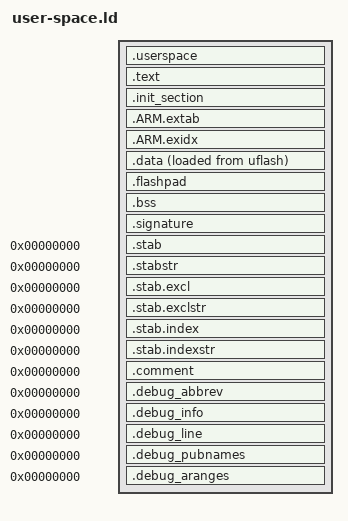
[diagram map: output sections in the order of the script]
/****************************************************************************
 * user-space.ld
 *
 *   Copyright (C) 2015 Gregory Nutt. All rights reserved.
 *   Author: Gregory Nutt <gnutt@nuttx.org>
 *
 * Redistribution and use in source and binary forms, with or without
 * modification, are permitted provided that the following conditions
 * are met:
 *
 * 1. Redistributions of source code must retain the above copyright
 *    notice, this list of conditions and the following disclaimer.
 * 2. Redistributions in binary form must reproduce the above copyright
 *    notice, this list of conditions and the following disclaimer in
 *    the documentation and/or other materials provided with the
 *    distribution.
 * 3. Neither the name NuttX nor the names of its contributors may be
 *    used to endorse or promote products derived from this software
 *    without specific prior written permission.
 *
 * THIS SOFTWARE IS PROVIDED BY THE COPYRIGHT HOLDERS AND CONTRIBUTORS
 * "AS IS" AND ANY EXPRESS OR IMPLIED WARRANTIES, INCLUDING, BUT NOT
 * LIMITED TO, THE IMPLIED WARRANTIES OF MERCHANTABILITY AND FITNESS
 * FOR A PARTICULAR PURPOSE ARE DISCLAIMED. IN NO EVENT SHALL THE
 * COPYRIGHT OWNER OR CONTRIBUTORS BE LIABLE FOR ANY DIRECT, INDIRECT,
 * INCIDENTAL, SPECIAL, EXEMPLARY, OR CONSEQUENTIAL DAMAGES (INCLUDING,
 * BUT NOT LIMITED TO, PROCUREMENT OF SUBSTITUTE GOODS OR SERVICES; LOSS
 * OF USE, DATA, OR PROFITS; OR BUSINESS INTERRUPTION) HOWEVER CAUSED
 * AND ON ANY THEORY OF LIABILITY, WHETHER IN CONTRACT, STRICT
 * LIABILITY, OR TORT (INCLUDING NEGLIGENCE OR OTHERWISE) ARISING IN
 * ANY WAY OUT OF THE USE OF THIS SOFTWARE, EVEN IF ADVISED OF THE
 * POSSIBILITY OF SUCH DAMAGE.
 *
 ****************************************************************************/

/* Include memory.ld before this script. */

EXTERN(userspace)
OUTPUT_ARCH(arm)

SECTIONS
{
    .userspace : {
        _stext = ABSOLUTE(.);
        KEEP(*(.userspace))
    } > uflash

    .text : {
        *(.text .text.*)
        *(.fixup)
        *(.gnu.warning)
        *(.rodata .rodata.*)
        *(.gnu.linkonce.t.*)
        *(.glue_7)
        *(.glue_7t)
        *(.got)
        *(.gcc_except_table)
        *(.gnu.linkonce.r.*)
    } > uflash

    .init_section : {
        _sinit = ABSOLUTE(.);
        KEEP(*(.init_array .init_array.*))
        _einit = ABSOLUTE(.);
    } > uflash

    .ARM.extab : {
        *(.ARM.extab*)
    } > uflash

    .ARM.exidx : {
        __exidx_start = ABSOLUTE(.);
        *(.ARM.exidx*)
        __exidx_end = ABSOLUTE(.);
    } > uflash

    .data : {
        _sdata = ABSOLUTE(.);
        *(.data .data.*)
        *(.gnu.linkonce.d.*)
        CONSTRUCTORS
        . = ALIGN(4);
        _edata = ABSOLUTE(.);
    } > usram AT > uflash

    _eronly = LOADADDR(.data);

    /* Pad the final loadable section to the STM32H7 flash write size. */
    .flashpad : {
        FILL(0xffffffff)
        BYTE(0xff)
        . = ALIGN(32);
        _etext = ABSOLUTE(.);
    } > uflash

    .bss (NOLOAD) : {
        _sbss = ABSOLUTE(.);
        *(.bss .bss.*)
        *(.gnu.linkonce.b.*)
        *(COMMON)
        /* The largest user static MPU region is 128 KiB. Its eight
         * subregions are 16 KiB; keep the following kernel heap outside
         * every user-accessible subregion, including alignment padding.
         */
        . = ALIGN(0x4000);
        _ebss = ABSOLUTE(.);
    } > usram

    ASSERT(_ebss <= ORIGIN(usram) + LENGTH(usram),
           "User data exceeds its protected SRAM window")
    ASSERT((_ebss & 0x3fff) == 0,
           "User bss end must align to an MPU subregion")

    /* The signature is appended at the end of the combined image. */
    .signature : {
        _boot_signature = ALIGN(4);
    } > uflash

    .stab 0 : { *(.stab) }
    .stabstr 0 : { *(.stabstr) }
    .stab.excl 0 : { *(.stab.excl) }
    .stab.exclstr 0 : { *(.stab.exclstr) }
    .stab.index 0 : { *(.stab.index) }
    .stab.indexstr 0 : { *(.stab.indexstr) }
    .comment 0 : { *(.comment) }
    .debug_abbrev 0 : { *(.debug_abbrev) }
    .debug_info 0 : { *(.debug_info) }
    .debug_line 0 : { *(.debug_line) }
    .debug_pubnames 0 : { *(.debug_pubnames) }
    .debug_aranges 0 : { *(.debug_aranges) }
}
